# a34g43x register map
Vendor: ABOV Semiconductor Co., Ltd.; File version: 1.0
CPU: CM4 r0p1, little endian, MPU, FPU, VTOR, 4 interrupt priority bits
Registers are 32-bit, read-write, reset 0x0 unless marked. A register's access mark holds for its fields unless they carry their own. Offsets are from the block's base; [hi:lo] are bit positions; {n}, {i} and the like mark numbered series; 'fields as' and 'values as' point back to an identical list.

## CANFD0 — CAN with Flexible Data Rate (CANFD)
Base 0x40010000
Same registers: CANFD1 0x40012000
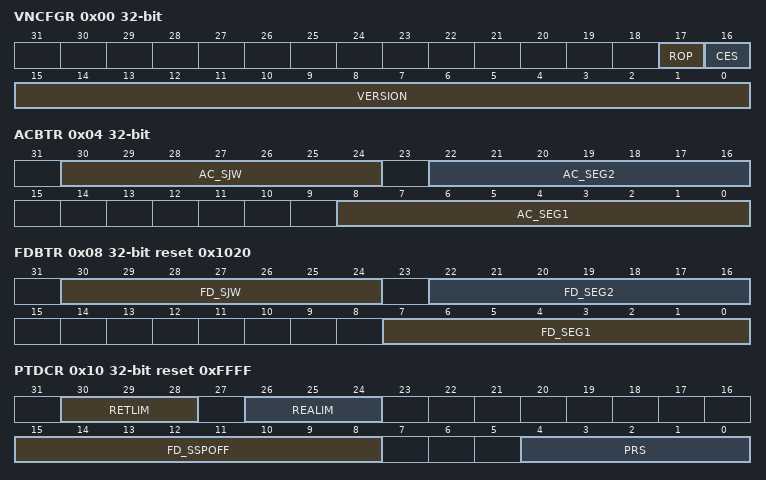
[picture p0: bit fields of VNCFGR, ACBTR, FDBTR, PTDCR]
0x00 VNCFGR — CANFD n Version and Node Configuration Register
  [17] ROP — Restricted Operation
    0=Disables restricted operation; 1=Enables restricted operation
  [16] CES — CAN Error Signaling
    0=Disable (Not support); 1=Enable CAN error signaling
  [15:0] VERSION — Version of CAN-CTRL
0x04 ACBTR — CANFD n Arbitration and Classic Bit Timing Register
  [30:24] AC_SJW — Synchronization Jump Width
  [22:16] AC_SEG2 — Bit Timing Segment 2
  [8:0] AC_SEG1 — Bit Timing Segment 1
0x08 FDBTR reset 0x1020 — CANFD n Flexible Data Bit Timing Register
  [30:24] FD_SJW — Synchronization Jump Width
  [22:16] FD_SEG2 — Bit Timing Segment 2
  [7:0] FD_SEG1 — Bit Timing Segment 1
0x10 PTDCR reset 0xFFFF — CANFD n Prescaler and Transmitter Delay Compensation Register
  [30:28] RETLIM — Retransmission Limit
    {v}={v+1}_attempts (v=0..6); 7=Unlimited
  [26:24] REALIM — Rearbitration Limit
    {v}={v+1}_attempts (v=0..6); 7=Unlimited
  [15:8] FD_SSPOFF — Secondary Sample Point Offset
  [4:0] PRS — Prescaler
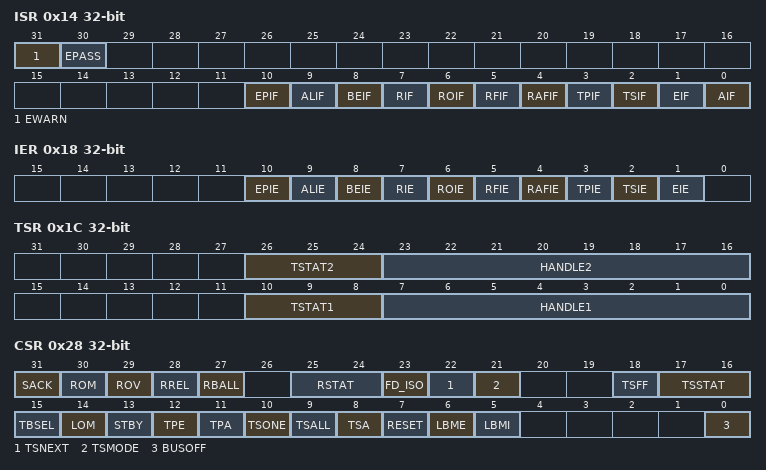
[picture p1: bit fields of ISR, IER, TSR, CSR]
0x14 ISR — CANFD n Interrupt Status Register
  [31] EWARN ro — Error warning limit reached
  [30] EPASS ro — Error Passive status
  [10] EPIF — Error passive interrupt flag
  [9] ALIF — Arbitration lost interrupt flag
  [8] BEIF — Bus error interrupt flag
  [7] RIF — Receive interrupt flag
  [6] ROIF — RB Overflow Interrupt Flag
  [5] RFIF — RB Full interrupt flag
  [4] RAFIF — RB Almost Full Interrupt Flag
  [3] TPIF — Transmission Primary Interrupt Flag
  [2] TSIF — Transmission Secondary Interrupt Flag
  [1] EIF — Error interrupt flag
  [0] AIF — Abort Interrupt flag
0x18 IER — CANFD n Interrupt Enable Register
  [10] EPIE — Enable the Error passive interrupt
  [9] ALIE — Enable the Arbitration lost interrupt
  [8] BEIE — Enable the Bus error interrupt
  [7] RIE — Enable the Receive interrupt
  [6] ROIE — Enable the RB overflow Interrupt
  [5] RFIE — Enable the RB full interrupt
  [4] RAFIE — Enable the RB Almost Full Interrupt Flag
  [3] TPIE — Enable the Transmission Primary Interrupt
  [2] TSIE — Enable the Transmission Secondary Interrupt
  [1] EIE — Enable the Error interrupt
0x1C TSR — CANFD n Transmit Status Register
  [26:24] TSTAT2 — TSTAT2 Transmission status code
    0=IDLE (No transmission in progress); 1=ONGOING (Transmission active without any issues); 2=LOST_ARBITRATION (Arbitration lost, re-arbitration may take place with respect to REALIM[2:0] bits in CANFDn_PTDCR register.); 3=TRANSMITTED (Transmission successfully completed); 4=ABORTED (Transmission aborted (TPA or TSA bit in CANFDn_CSR register).); 5=DISTURBED (Transmission error. Re-transmission may take place with respect to RETLIM[2:0] bits in CANFDn_PTDCR register); 6=REJECTED (Misconfiguration of the frame format in the LLC frame.)
  [23:16] HANDLE2 — TSTAT2 Handle for frame identification
  [10:8] TSTAT1 — TSTAT1 Enable the Bus error interrupt
    values as TSTAT2
  [7:0] HANDLE1 — TSTAT1 Handle for frame identification
0x28 CSR — CANFD n Control and Status Register
  [31] SACK — Self Acknowledge
  [30] ROM — Receive buffer overflow mode
  [29] ROV — Receive buffer overflow status
  [28] RREL — Receive buffer release
  [27] RBALL — Receive Buffer stores ALL data frames
  [25:24] RSTAT — Receive buffer status
  [23] FD_ISO — FAN FD ISO mode
  [22] TSNEXT — Transmit buffer Secondary NEXT
  [21] TSMODE — Transmit buffer Secondary operation mode
  [18] TSFF — Transmit Secondary buffer Full Flag
  [17:16] TSSTAT — Transmit secondary status
  [15] TBSEL — Transmit Buffer Select
  [14] LOM — Listen Only Mode
  [13] STBY — Transceiver Standby Mode
  [12] TPE — Transmit Primary Enable
  [11] TPA — Transmit Primary Abort
  [10] TSONE — Transmit Secondary ONE frame
  [9] TSALL — Transmit Secondary ALL frames
  [8] TSA — Transmit Secondary Abort
  [7] RESET — Software reset
  [6] LBME — Loop Back Mode, External
  [5] LBMI — Loop Back Mode, Internal
  [0] BUSOFF
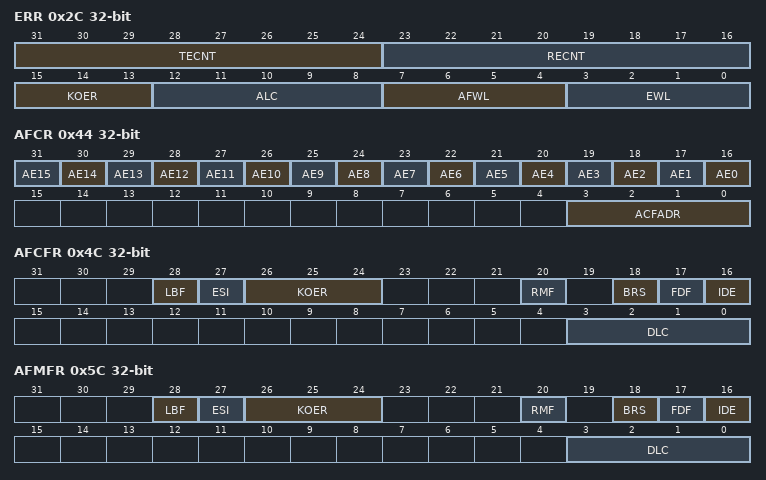
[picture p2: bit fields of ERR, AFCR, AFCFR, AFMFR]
0x2C ERR — CANFD n Error Register
  [31:24] TECNT — Transmit Error Count
  [23:16] RECNT — Receive Error Count
  [15:13] KOER — Kind Of Error (error code)
  [12:8] ALC — Arbitration Lost Capture
  [7:4] AFWL — Receive buffer Almost Full Warning Limit
  [3:0] EWL — Error Warning Limit = (EWL+1)*8. Possible Limit values
0x44 AFCR — CANFD n Acceptance Filter Control Register
  [n+16] AE{n} (n=0..15) — Enable the Acceptance filter {n}
  [3:0] ACFADR — acceptance filter address
0x48 AFCIR — CANFD n Acceptance Filter Code Identifier Register
  [28:0] ID — Frame Identifier
0x4C AFCFR — CANFD n Acceptance Filter Code Format Register
  [28] LBF — Loop-Back Frame
  [27] ESI — Error State Indicator
  [26:24] KOER — Kind of Error
    0=NO_ERR (no error); 1=BIT_ERR (bit error); 2=FORM_ERR (form error); 3=STUFF_ERR (stuff error); 4=ACK_ERR (acknowledgement error); 5=CRC_ERR (crc error); 6=OTHER_ERR (other error)
  [20] RMF — Remote Frame
  [18] BRS — CAN FD Bit Rate Switch Enable
  [17] FDF — CAN FD frame Format
  [16] IDE — Identifier Extension
  [3:0] DLC — Data Length Code
    {v}={v}_BYTE (v=0..8); 9=8_or_12_BYTE (CAN CC 8 BYTE, CAN FD 12 BYTE); 10=8_or_16_BYTE (CAN CC 8 BYTE, CAN FD 16 BYTE); 11=8_or_20_BYTE (CAN CC 8 BYTE, CAN FD 20 BYTE); 12=8_or_24_BYTE (CAN CC 8 BYTE, CAN FD 24 BYTE); 13=8_or_32_BYTE (CAN CC 8 BYTE, CAN FD 32 BYTE); 14=8_or_48_BYTE (CAN CC 8 BYTE, CAN FD 48 BYTE); 15=8_or_64_BYTE (CAN CC 8 BYTE, CAN FD 64 BYTE)
0x50 AFCTR — CANFD n Acceptance Filter Code Type Register
  [31:24] HANDLE — Handle for frame identification
0x58 AFMIR — CANFD n Acceptance Filter Mask Identifier Register
  [28:0] ID — Frame Identifier
0x5C AFMFR — CANFD n Acceptance Filter Mask Format Register
  fields as AFCFR
0x60 AFMTR — CANFD n Acceptance Filter Mask Type Register
  [31:24] HANDLE — Handle for frame identification
0x70 RBIR — CANFD n Receive Buffer Identifier Register
  [28:0] ID — Frame Identifier
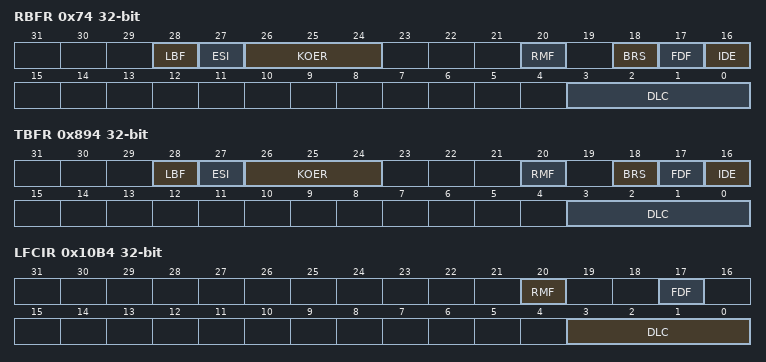
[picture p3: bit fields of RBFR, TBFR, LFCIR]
0x74 RBFR — CANFD n Receive Buffer Format Register
  fields as AFCFR
0x78 RBTR — CANFD n Receive Buffer Type Register
  [31:24] HANDLE — Handle for frame identification
0x80 RBPDR — CANFD n Receive Buffer Payload Data Register
  [31:0] RBPDR — Payload data of the frame
0x890 TBIR — CANFD n Transmit Buffer Identifier Register
  [28:0] ID — Frame Identifier
0x894 TBFR — CANFD n Transmit Buffer Format Register
  fields as AFCFR
0x898 TBTR — CANFD n Transmit Buffer Type Register
  [31:24] HANDLE — Handle for frame identification
0x8A0 TBPDR — CANFD n Transmit Buffer Payload Data Register
  [31:0] TBPDR — Payload data of the frame
0x10B0 TSCFGR — CANFD n Transmit Stream Configuration Register
  [0] RBEN — Enable the reception buffer
0x10B4 LFCIR — CANFD n LLC Frame Calculator Input Register
  [20] RMF — Remote Frame
  [17] FDF — CAN FD frame Format
  [3:0] DLC — Data Length Code
    values as AFCFR.DLC
0x10B8 LFCOR — CANFD n LLC Frame Calculator Output Register
  [15:0] LPB — LLC frame Payload Bytes
